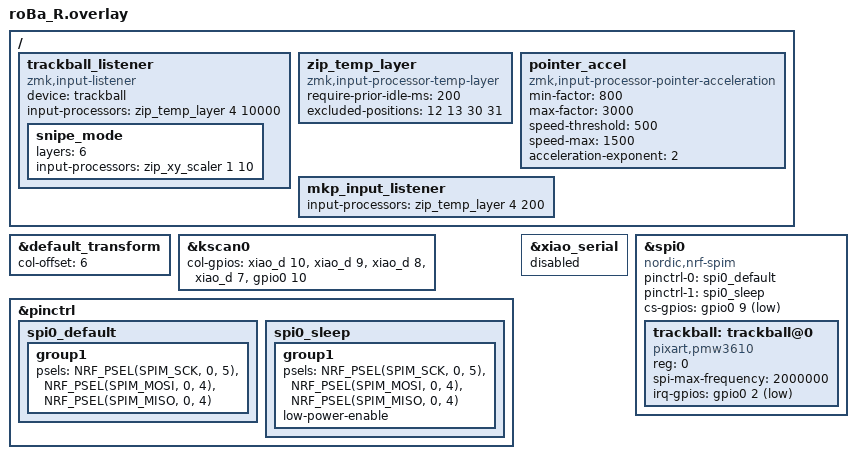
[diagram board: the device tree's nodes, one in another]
#include "roBa.dtsi"
#include <input/processors.dtsi>
#include <behaviors/input_gestures_accel.dtsi>

&default_transform {
    col-offset = <6>;
};

&kscan0 {
        col-gpios
            = <&xiao_d 10 GPIO_ACTIVE_HIGH>
            , <&xiao_d 9 GPIO_ACTIVE_HIGH>
            , <&xiao_d 8 GPIO_ACTIVE_HIGH>
            , <&xiao_d 7 GPIO_ACTIVE_HIGH>
            , <&gpio0 10 GPIO_ACTIVE_HIGH>
            ;
};

/ {
    trackball_listener {
        status = "okay";
        compatible = "zmk,input-listener";
        device = <&trackball>;
    };
};

&pinctrl {
    spi0_default: spi0_default {
        group1 {
            psels = <NRF_PSEL(SPIM_SCK, 0, 5)>,
                <NRF_PSEL(SPIM_MOSI, 0, 4)>,
                <NRF_PSEL(SPIM_MISO, 0, 4)>;
        };
    };

    spi0_sleep: spi0_sleep {
        group1 {
            psels = <NRF_PSEL(SPIM_SCK, 0, 5)>,
                <NRF_PSEL(SPIM_MOSI, 0, 4)>,
                <NRF_PSEL(SPIM_MISO, 0, 4)>;
            low-power-enable;
        };
    };
};

&xiao_serial { status = "disabled"; };

&spi0 {
    status = "okay";
    compatible = "nordic,nrf-spim";
    pinctrl-0 = <&spi0_default>;
    pinctrl-1 = <&spi0_sleep>;
    pinctrl-names = "default", "sleep";
    cs-gpios = <&gpio0 9 GPIO_ACTIVE_LOW>;

    trackball: trackball@0 {
        status = "okay";
        compatible = "pixart,pmw3610";
        reg = <0>;
        spi-max-frequency = <2000000>;
        irq-gpios = <&gpio0 2 (GPIO_ACTIVE_LOW | GPIO_PULL_UP)>;
    };
};

/ {
    /omit-if-no-ref/ zip_temp_layer: zip_temp_layer {
        compatible = "zmk,input-processor-temp-layer";
        #input-processor-cells = <2>;
        require-prior-idle-ms = <200>;
        excluded-positions = <
            12
            13
            30
            31
        >;
    };
    // ── 1. 加速度パラメータの調整定義 ──
    pointer_accel: pointer_accel {
        compatible = "zmk,input-processor-pointer-acceleration";
        #input-processor-cells = <0>;
        
        // roBa用に微調整しやすいおすすめの初期値
        min-factor = <800>;          // 遅い時の速度（80%に減速させて精密操作）
        max-factor = <3000>;         // 最大加速時の速度（3倍）
        speed-threshold = <500>;     // 加速が始まり始める閾値
        speed-max = <1500>;          // 最大加速に達する速度
        acceleration-exponent = <2>; // 2次曲線でスムーズに加速
    };
    // ── 2. roBaのインプットリスナーへ適用 ──
    // ※既存の &trackball_listener や &ib_handler 内の input-processors を書き
    trackball_listener {
        compatible = "zmk,input-listener";
        device = <&trackball>;
        input-processors = <&zip_temp_layer 4 10000>;
        snipe_mode {
            layers = <6>;
            input-processors = <&zip_xy_scaler 1 10>;
        };
    };

    mkp_input_listener {
        input-processors = <&zip_temp_layer 4 200>;
    };
};
